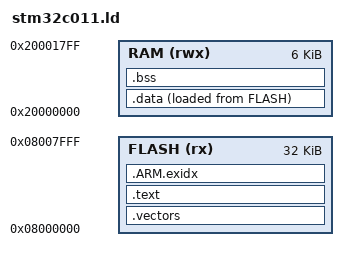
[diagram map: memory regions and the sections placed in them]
ENTRY(Reset_Handler)
MEMORY { FLASH (rx) : ORIGIN = 0x08000000, LENGTH = 32K
         RAM (rwx) : ORIGIN = 0x20000000, LENGTH = 6K }
_stack_top = ORIGIN(RAM) + LENGTH(RAM);
SECTIONS {
  .vectors : { KEEP(*(.vectors)) } > FLASH
  .text : { *(.text*) *(.rodata*) . = ALIGN(4); } > FLASH
  .ARM.exidx : { *(.ARM.exidx*) } > FLASH
  .data : { . = ALIGN(4); _sdata = .; *(.data*) . = ALIGN(4); _edata = .; } > RAM AT > FLASH
  _sidata = LOADADDR(.data);
  .bss (NOLOAD) : { . = ALIGN(4); _sbss = .; *(.bss*) *(COMMON) . = ALIGN(4); _ebss = .; } > RAM
  ASSERT(_ebss + 1024 <= _stack_top, "Reserve at least 1KiB stack")
}
